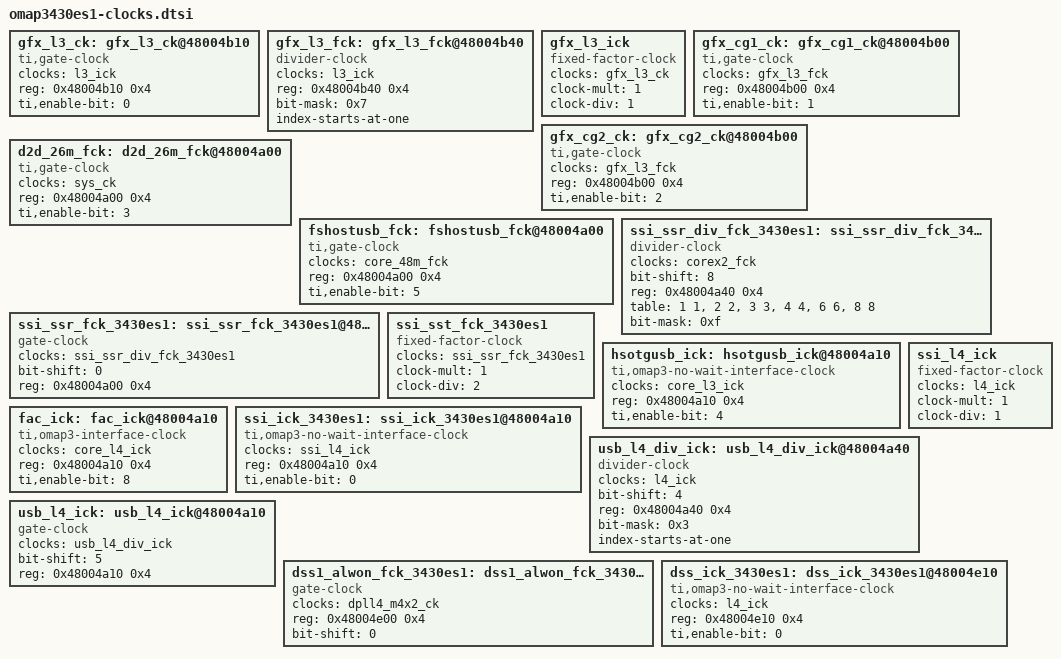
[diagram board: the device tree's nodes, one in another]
/*
 * Device Tree Source for OMAP3430 ES1 clock data
 *
 * Copyright (C) 2013 Texas Instruments, Inc.
 *
 * This program is free software; you can redistribute it and/or modify
 * it under the terms of the GNU General Public License version 2 as
 * published by the Free Software Foundation.
 */

gfx_l3_ck: gfx_l3_ck@48004b10 {
	#clock-cells = <0>;
	compatible = "ti,gate-clock";
	clocks = <&l3_ick>;
	reg = <0x48004b10 0x4>;
	ti,enable-bit = <0>;
};

gfx_l3_fck: gfx_l3_fck@48004b40 {
	#clock-cells = <0>;
	compatible = "divider-clock";
	clocks = <&l3_ick>;
	reg = <0x48004b40 0x4>;
	bit-mask = <0x7>;
	index-starts-at-one;
};

gfx_l3_ick: gfx_l3_ick {
	#clock-cells = <0>;
	compatible = "fixed-factor-clock";
	clocks = <&gfx_l3_ck>;
	clock-mult = <1>;
	clock-div = <1>;
};

gfx_cg1_ck: gfx_cg1_ck@48004b00 {
	#clock-cells = <0>;
	compatible = "ti,gate-clock";
	clocks = <&gfx_l3_fck>;
	reg = <0x48004b00 0x4>;
	ti,enable-bit = <1>;
};

gfx_cg2_ck: gfx_cg2_ck@48004b00 {
	#clock-cells = <0>;
	compatible = "ti,gate-clock";
	clocks = <&gfx_l3_fck>;
	reg = <0x48004b00 0x4>;
	ti,enable-bit = <2>;
};

d2d_26m_fck: d2d_26m_fck@48004a00 {
	#clock-cells = <0>;
	compatible = "ti,gate-clock";
	clocks = <&sys_ck>;
	reg = <0x48004a00 0x4>;
	ti,enable-bit = <3>;
};

fshostusb_fck: fshostusb_fck@48004a00 {
	#clock-cells = <0>;
	compatible = "ti,gate-clock";
	clocks = <&core_48m_fck>;
	reg = <0x48004a00 0x4>;
	ti,enable-bit = <5>;
};

ssi_ssr_div_fck_3430es1: ssi_ssr_div_fck_3430es1@48004a40 {
	#clock-cells = <0>;
	compatible = "divider-clock";
	clocks = <&corex2_fck>;
	bit-shift = <8>;
	reg = <0x48004a40 0x4>;
	table = < 1 1 >, < 2 2 >, < 3 3 >, < 4 4 >, < 6 6 >, < 8 8 >;
	bit-mask = <0xf>;
};

ssi_ssr_fck_3430es1: ssi_ssr_fck_3430es1@48004a00 {
	#clock-cells = <0>;
	compatible = "gate-clock";
	clocks = <&ssi_ssr_div_fck_3430es1>;
	bit-shift = <0>;
	reg = <0x48004a00 0x4>;
};

ssi_sst_fck_3430es1: ssi_sst_fck_3430es1 {
	#clock-cells = <0>;
	compatible = "fixed-factor-clock";
	clocks = <&ssi_ssr_fck_3430es1>;
	clock-mult = <1>;
	clock-div = <2>;
};

hsotgusb_ick: hsotgusb_ick@48004a10 {
	#clock-cells = <0>;
	compatible = "ti,omap3-no-wait-interface-clock";
	clocks = <&core_l3_ick>;
	reg = <0x48004a10 0x4>;
	ti,enable-bit = <4>;
};

fac_ick: fac_ick@48004a10 {
	#clock-cells = <0>;
	compatible = "ti,omap3-interface-clock";
	clocks = <&core_l4_ick>;
	reg = <0x48004a10 0x4>;
	ti,enable-bit = <8>;
};

ssi_l4_ick: ssi_l4_ick {
	#clock-cells = <0>;
	compatible = "fixed-factor-clock";
	clocks = <&l4_ick>;
	clock-mult = <1>;
	clock-div = <1>;
};

ssi_ick_3430es1: ssi_ick_3430es1@48004a10 {
	#clock-cells = <0>;
	compatible = "ti,omap3-no-wait-interface-clock";
	clocks = <&ssi_l4_ick>;
	reg = <0x48004a10 0x4>;
	ti,enable-bit = <0>;
};

usb_l4_div_ick: usb_l4_div_ick@48004a40 {
	#clock-cells = <0>;
	compatible = "divider-clock";
	clocks = <&l4_ick>;
	bit-shift = <4>;
	reg = <0x48004a40 0x4>;
	bit-mask = <0x3>;
	index-starts-at-one;
};

usb_l4_ick: usb_l4_ick@48004a10 {
	#clock-cells = <0>;
	compatible = "gate-clock";
	clocks = <&usb_l4_div_ick>;
	bit-shift = <5>;
	reg = <0x48004a10 0x4>;
};

dss1_alwon_fck_3430es1: dss1_alwon_fck_3430es1@48004e00 {
	#clock-cells = <0>;
	compatible = "gate-clock";
	clocks = <&dpll4_m4x2_ck>;
	reg = <0x48004e00 0x4>;
	bit-shift = <0>;
};

dss_ick_3430es1: dss_ick_3430es1@48004e10 {
	#clock-cells = <0>;
	compatible = "ti,omap3-no-wait-interface-clock";
	clocks = <&l4_ick>;
	reg = <0x48004e10 0x4>;
	ti,enable-bit = <0>;
};
